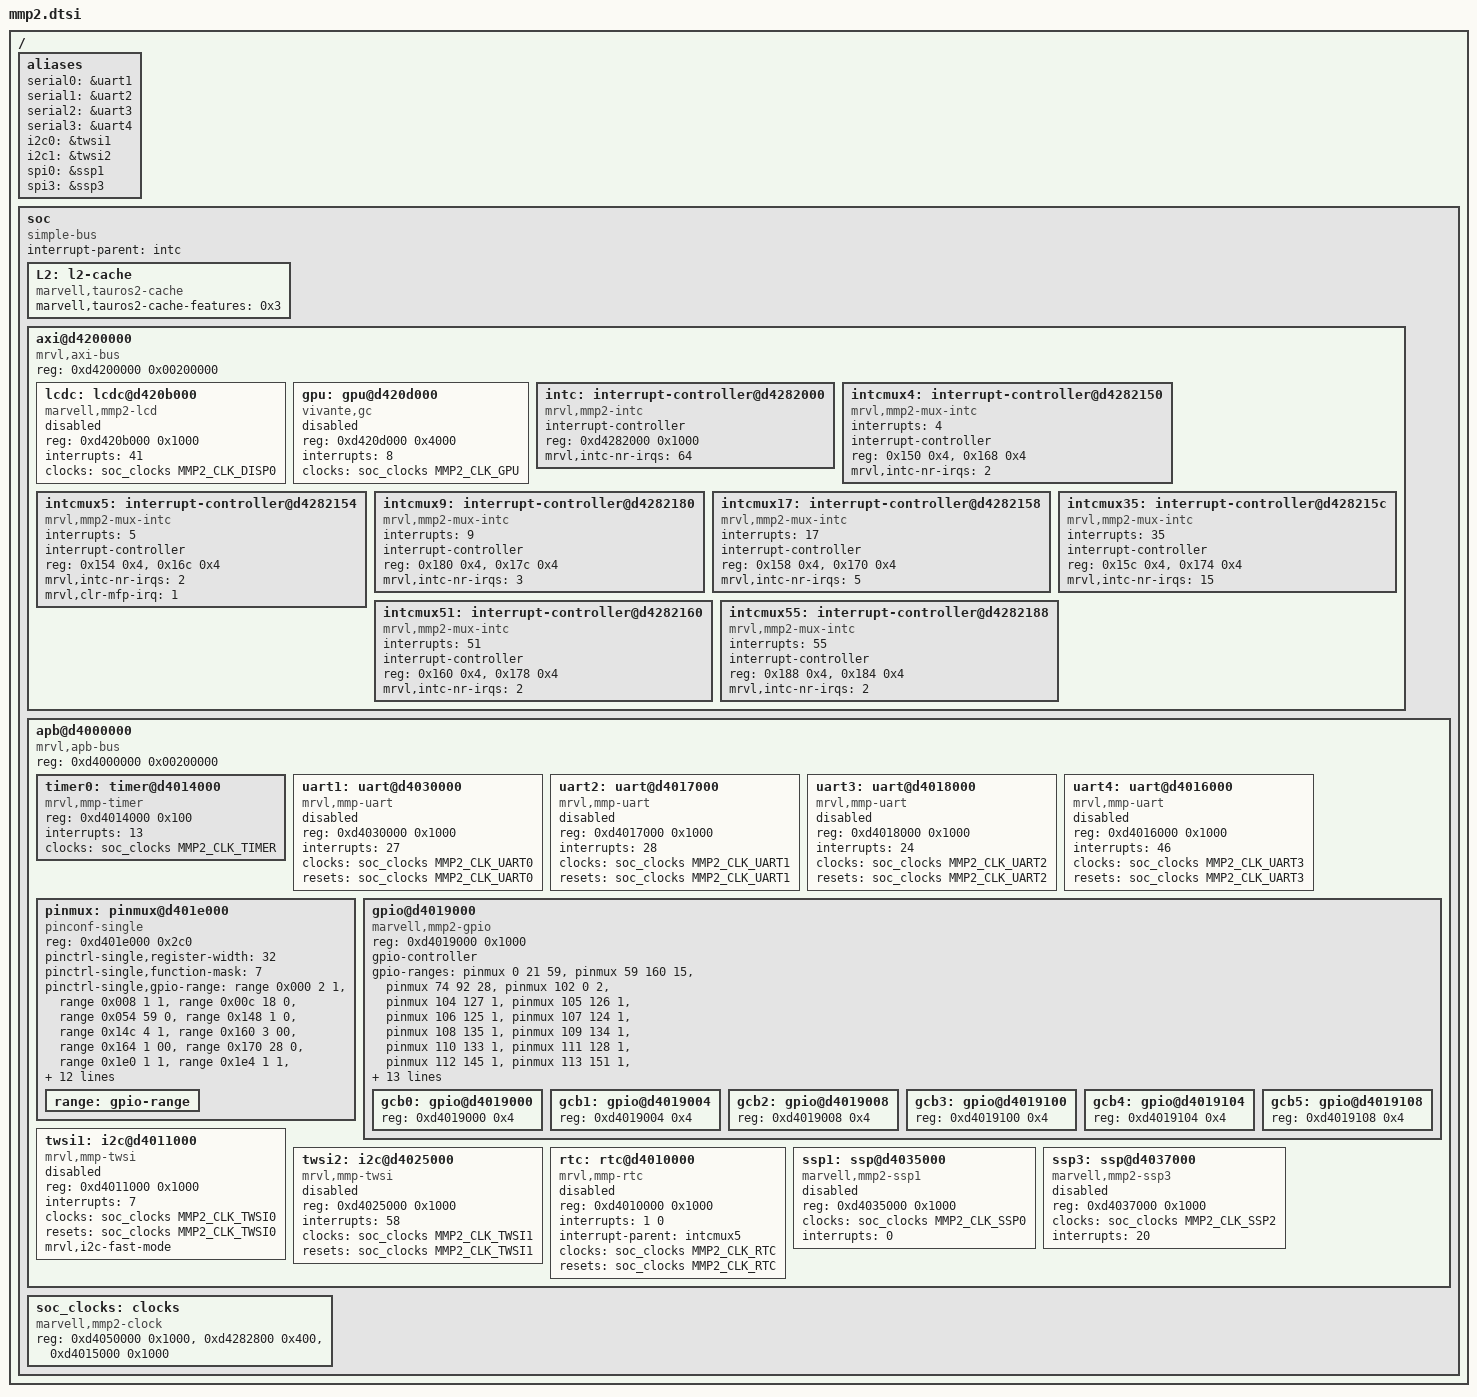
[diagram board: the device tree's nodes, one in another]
/*
 *  Copyright (C) 2012 Marvell Technology Group Ltd.
 *  Author: Haojian Zhuang <haojian.zhuang@marvell.com>
 *
 *  This program is free software; you can redistribute it and/or modify
 *  it under the terms of the GNU General Public License version 2 as
 *  publishhed by the Free Software Foundation.
 */

#include "skeleton.dtsi"
#include <dt-bindings/clock/marvell,mmp2.h>

/ {
	aliases {
		serial0 = &uart1;
		serial1 = &uart2;
		serial2 = &uart3;
		serial3 = &uart4;
		i2c0 = &twsi1;
		i2c1 = &twsi2;
		spi0 = &ssp1;
		spi3 = &ssp3;
	};

	soc {
		#address-cells = <1>;
		#size-cells = <1>;
		compatible = "simple-bus";
		interrupt-parent = <&intc>;
		ranges;

		L2: l2-cache {
			compatible = "marvell,tauros2-cache";
			marvell,tauros2-cache-features = <0x3>;
		};

		axi@d4200000 {	/* AXI */
			compatible = "mrvl,axi-bus", "simple-bus";
			#address-cells = <1>;
			#size-cells = <1>;
			reg = <0xd4200000 0x00200000>;
			ranges;

			lcdc: lcdc@d420b000 {
				compatible = "marvell,mmp2-lcd";
				reg = <0xd420b000 0x1000>;
				interrupts = <41>;
				clocks = <&soc_clocks MMP2_CLK_DISP0>;
				clock-names = "axiclk";
				status = "disabled";
			};

			gpu: gpu@d420d000 {
				compatible = "vivante,gc";
				reg = <0xd420d000 0x4000>;
				interrupts = <8>;
				clocks = <&soc_clocks MMP2_CLK_GPU>;
				clock-names = "core";
				/* power-domains = <&gpu_domain>; */
				status = "disabled";
			};

			intc: interrupt-controller@d4282000 {
				compatible = "mrvl,mmp2-intc";
				interrupt-controller;
				#interrupt-cells = <1>;
				reg = <0xd4282000 0x1000>;
				mrvl,intc-nr-irqs = <64>;
			};

			intcmux4: interrupt-controller@d4282150 {
				compatible = "mrvl,mmp2-mux-intc";
				interrupts = <4>;
				interrupt-controller;
				#interrupt-cells = <1>;
				reg = <0x150 0x4>, <0x168 0x4>;
				reg-names = "mux status", "mux mask";
				mrvl,intc-nr-irqs = <2>;
			};

			intcmux5: interrupt-controller@d4282154 {
				compatible = "mrvl,mmp2-mux-intc";
				interrupts = <5>;
				interrupt-controller;
				#interrupt-cells = <1>;
				reg = <0x154 0x4>, <0x16c 0x4>;
				reg-names = "mux status", "mux mask";
				mrvl,intc-nr-irqs = <2>;
				mrvl,clr-mfp-irq = <1>;
			};

			intcmux9: interrupt-controller@d4282180 {
				compatible = "mrvl,mmp2-mux-intc";
				interrupts = <9>;
				interrupt-controller;
				#interrupt-cells = <1>;
				reg = <0x180 0x4>, <0x17c 0x4>;
				reg-names = "mux status", "mux mask";
				mrvl,intc-nr-irqs = <3>;
			};

			intcmux17: interrupt-controller@d4282158 {
				compatible = "mrvl,mmp2-mux-intc";
				interrupts = <17>;
				interrupt-controller;
				#interrupt-cells = <1>;
				reg = <0x158 0x4>, <0x170 0x4>;
				reg-names = "mux status", "mux mask";
				mrvl,intc-nr-irqs = <5>;
			};

			intcmux35: interrupt-controller@d428215c {
				compatible = "mrvl,mmp2-mux-intc";
				interrupts = <35>;
				interrupt-controller;
				#interrupt-cells = <1>;
				reg = <0x15c 0x4>, <0x174 0x4>;
				reg-names = "mux status", "mux mask";
				mrvl,intc-nr-irqs = <15>;
			};

			intcmux51: interrupt-controller@d4282160 {
				compatible = "mrvl,mmp2-mux-intc";
				interrupts = <51>;
				interrupt-controller;
				#interrupt-cells = <1>;
				reg = <0x160 0x4>, <0x178 0x4>;
				reg-names = "mux status", "mux mask";
				mrvl,intc-nr-irqs = <2>;
			};

			intcmux55: interrupt-controller@d4282188 {
				compatible = "mrvl,mmp2-mux-intc";
				interrupts = <55>;
				interrupt-controller;
				#interrupt-cells = <1>;
				reg = <0x188 0x4>, <0x184 0x4>;
				reg-names = "mux status", "mux mask";
				mrvl,intc-nr-irqs = <2>;
			};
		};

		apb@d4000000 {	/* APB */
			compatible = "mrvl,apb-bus", "simple-bus";
			#address-cells = <1>;
			#size-cells = <1>;
			reg = <0xd4000000 0x00200000>;
			ranges;

			timer0: timer@d4014000 {
				compatible = "mrvl,mmp-timer";
				reg = <0xd4014000 0x100>;
				interrupts = <13>;
				clocks = <&soc_clocks MMP2_CLK_TIMER>;
			};

			uart1: uart@d4030000 {
				compatible = "mrvl,mmp-uart";
				reg = <0xd4030000 0x1000>;
				interrupts = <27>;
				clocks = <&soc_clocks MMP2_CLK_UART0>;
				resets = <&soc_clocks MMP2_CLK_UART0>;
				status = "disabled";
			};

			uart2: uart@d4017000 {
				compatible = "mrvl,mmp-uart";
				reg = <0xd4017000 0x1000>;
				interrupts = <28>;
				clocks = <&soc_clocks MMP2_CLK_UART1>;
				resets = <&soc_clocks MMP2_CLK_UART1>;
				status = "disabled";
			};

			uart3: uart@d4018000 {
				compatible = "mrvl,mmp-uart";
				reg = <0xd4018000 0x1000>;
				interrupts = <24>;
				clocks = <&soc_clocks MMP2_CLK_UART2>;
				resets = <&soc_clocks MMP2_CLK_UART2>;
				status = "disabled";
			};

			uart4: uart@d4016000 {
				compatible = "mrvl,mmp-uart";
				reg = <0xd4016000 0x1000>;
				interrupts = <46>;
				clocks = <&soc_clocks MMP2_CLK_UART3>;
				resets = <&soc_clocks MMP2_CLK_UART3>;
				status = "disabled";
			};

			pinmux: pinmux@d401e000 {
				compatible = "pinconf-single";
				reg = <0xd401e000 0x2c0>;
				#address-cells = <1>;
				#size-cells = <1>;
				ranges;
				pinctrl-single,register-width = <32>;
				pinctrl-single,function-mask = <7>;
				pinctrl-single,gpio-range =
					<&range 0x000  2  1>, /* GPIO102 - GPIO103 */
					<&range 0x008  1  1>, /* GPIO142 */
					<&range 0x00c 18  0>, /* GPIO124 - GPIO141 */
					<&range 0x054 59  0>, /* GPIO0 - GPIO58 */
					<&range 0x148  1  0>, /* GPIO123 */
					<&range 0x14c  4  1>, /* GPIO156 - GPIO159 */
					<&range 0x160  3 00>, /* G_CLKREQ, VCXO_REQ, VCXO_OUT, */
					<&range 0x164  1 00>, /* GPIO114 */
					<&range 0x170 28  0>, /* GPIO74 - GPIO101 */
					<&range 0x1e0  1  1>, /* GPIO168 */
					<&range 0x1e4  1  1>, /* GPIO167 */
					<&range 0x1e8  1  1>, /* GPIO166 */
					<&range 0x1ec  1  1>, /* GPIO165 */
					<&range 0x1f0  1  1>, /* GPIO107 */
					<&range 0x1f4  1  1>, /* GPIO106 */
					<&range 0x1f8  1  1>, /* GPIO105 */
					<&range 0x1fc  1  1>, /* GPIO104 */
					<&range 0x200  1  1>, /* GPIO111 */
					<&range 0x204  1  1>, /* GPIO164 */
					<&range 0x208  1  1>, /* GPIO163 */
					<&range 0x20c  1  1>, /* GPIO162 */
					<&range 0x210  1  1>, /* GPIO161 */
					<&range 0x214  1  1>, /* GPIO110 */
					<&range 0x218  1  1>, /* GPIO109 */
					<&range 0x21c  1  1>, /* GPIO108 */
					<&range 0x220  9  1>, /* GPIO143 - GPIO151 */
					<&range 0x244  1  1>, /* GPIO112 */
					<&range 0x248  1  1>, /* GPIO152 */
					<&range 0x250  1  1>, /* GPIO160 */
					<&range 0x254  2  1>, /* GPIO154 - GPIO155 */
					<&range 0x25c  1  1>, /* GPIO113 */
					<&range 0x260  8  0>, /* GPIO115 - GPIO122 */
					<&range 0x280 15  0>, /* GPIO59 - GPIO73 */
					<&range 0x2bc  2 00>; /* TWSI4_SCL, TWSI4_SDA */

				range: gpio-range {
					#pinctrl-single,gpio-range-cells = <3>;
				};
			};

			gpio@d4019000 {
				compatible = "marvell,mmp2-gpio";
				#address-cells = <1>;
				#size-cells = <1>;
				reg = <0xd4019000 0x1000>;
				gpio-controller;
				#gpio-cells = <2>;
				gpio-ranges =
					<&pinmux   0  21 59>,
					<&pinmux  59 160 15>,
					<&pinmux  74  92 28>,
					<&pinmux 102   0  2>,
					<&pinmux 104 127  1>,
					<&pinmux 105 126  1>,
					<&pinmux 106 125  1>,
					<&pinmux 107 124  1>,
					<&pinmux 108 135  1>,
					<&pinmux 109 134  1>,
					<&pinmux 110 133  1>,
					<&pinmux 111 128  1>,
					<&pinmux 112 145  1>,
					<&pinmux 113 151  1>,
					<&pinmux 115 152  8>,
					<&pinmux 123  82  1>,
					<&pinmux 124   3 18>,
					<&pinmux 142   2  1>,
					<&pinmux 143 136  9>,
					<&pinmux 152 146  1>,
					<&pinmux 154 149  2>,
					<&pinmux 156  83  4>,
					<&pinmux 160 148  1>,
					<&pinmux 161 132  1>,
					<&pinmux 162 131  1>,
					<&pinmux 163 130  1>,
					<&pinmux 164 129  1>,
					<&pinmux 165 123  1>,
					<&pinmux 166 122  1>,
					<&pinmux 167 121  1>,
					<&pinmux 168 120  1>;
				interrupts = <49>;
				interrupt-names = "gpio_mux";
				clocks = <&soc_clocks MMP2_CLK_GPIO>;
				resets = <&soc_clocks MMP2_CLK_GPIO>;
				interrupt-controller;
				#interrupt-cells = <1>;
				ranges;

				gcb0: gpio@d4019000 {
					reg = <0xd4019000 0x4>;
				};

				gcb1: gpio@d4019004 {
					reg = <0xd4019004 0x4>;
				};

				gcb2: gpio@d4019008 {
					reg = <0xd4019008 0x4>;
				};

				gcb3: gpio@d4019100 {
					reg = <0xd4019100 0x4>;
				};

				gcb4: gpio@d4019104 {
					reg = <0xd4019104 0x4>;
				};

				gcb5: gpio@d4019108 {
					reg = <0xd4019108 0x4>;
				};
			};

			twsi1: i2c@d4011000 {
				compatible = "mrvl,mmp-twsi";
				reg = <0xd4011000 0x1000>;
				interrupts = <7>;
				clocks = <&soc_clocks MMP2_CLK_TWSI0>;
				resets = <&soc_clocks MMP2_CLK_TWSI0>;
				#address-cells = <1>;
				#size-cells = <0>;
				mrvl,i2c-fast-mode;
				status = "disabled";
			};

			twsi2: i2c@d4025000 {
				compatible = "mrvl,mmp-twsi";
				reg = <0xd4025000 0x1000>;
				interrupts = <58>;
				clocks = <&soc_clocks MMP2_CLK_TWSI1>;
				resets = <&soc_clocks MMP2_CLK_TWSI1>;
				status = "disabled";
			};

			rtc: rtc@d4010000 {
				compatible = "mrvl,mmp-rtc";
				reg = <0xd4010000 0x1000>;
				interrupts = <1 0>;
				interrupt-names = "rtc 1Hz", "rtc alarm";
				interrupt-parent = <&intcmux5>;
				clocks = <&soc_clocks MMP2_CLK_RTC>;
				resets = <&soc_clocks MMP2_CLK_RTC>;
				status = "disabled";
			};

			ssp1: ssp@d4035000 {
				compatible = "marvell,mmp2-ssp1";
				reg = <0xd4035000 0x1000>;
				clocks = <&soc_clocks MMP2_CLK_SSP0>;
				interrupts = <0>;
				status = "disabled";
			};

			ssp3: ssp@d4037000 {
				compatible = "marvell,mmp2-ssp3";
				reg = <0xd4037000 0x1000>;
				clocks = <&soc_clocks MMP2_CLK_SSP2>;
				interrupts = <20>;
				status = "disabled";
			};
		};

		soc_clocks: clocks{
			compatible = "marvell,mmp2-clock";
			reg = <0xd4050000 0x1000>,
			      <0xd4282800 0x400>,
			      <0xd4015000 0x1000>;
			reg-names = "mpmu", "apmu", "apbc";
			#clock-cells = <1>;
			#reset-cells = <1>;
		};
	};
};
